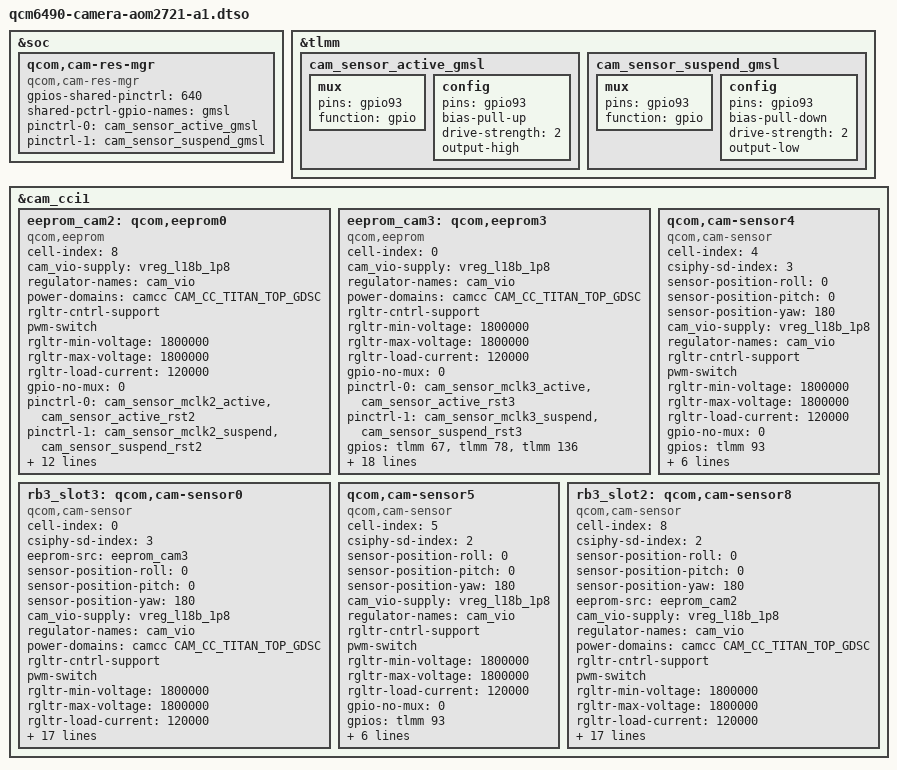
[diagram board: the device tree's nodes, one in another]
// SPDX-License-Identifier: BSD-3-Clause
/*
 * Copyright (c) 2023 Qualcomm Innovation Center, Inc. All rights reserved.
 */
/dts-v1/;
/plugin/;

#include <dt-bindings/clock/qcom,gcc-sc7280.h>
#include <dt-bindings/clock/qcom,camcc-sc7280.h>
#include <dt-bindings/interconnect/qcom,sc7280.h>
#include <dt-bindings/interrupt-controller/arm-gic.h>
#include <dt-bindings/power/qcom-rpmpd.h>

#include "qcm6490-camera-rb3.dtsi"

&soc {
	qcom,cam-res-mgr {
		compatible = "qcom,cam-res-mgr";
		status = "ok";
		gpios-shared-pinctrl = <640>;
		shared-pctrl-gpio-names = "gmsl";
		pinctrl-names = "gmsl_active", "gmsl_suspend";
		pinctrl-0 = <&cam_sensor_active_gmsl>;
		pinctrl-1 = <&cam_sensor_suspend_gmsl>;
	};
};
&tlmm {
	cam_sensor_active_gmsl: cam_sensor_active_gmsl {
		/* GMSL_ENABLE */
		mux {
			pins = "gpio93";
			function = "gpio";
		};

		config {
			pins = "gpio93";
			bias-pull-up;
			drive-strength = <2>; /* 2 MA */
			output-high;
		};
	};

	cam_sensor_suspend_gmsl: cam_sensor_suspend_gmsl {
		/* GMSL_ENABLE */
		mux {
			pins = "gpio93";
			function = "gpio";
		};

		config {
			pins = "gpio93";
			bias-pull-down; /* PULL DOWN */
			drive-strength = <2>; /* 2 MA */
			output-low;
		};
	};
};

&cam_cci1 {
	eeprom_cam2: qcom,eeprom0 {
		cell-index = <8>;
		compatible = "qcom,eeprom";
		cam_vio-supply = <&vreg_l18b_1p8>;
		regulator-names = "cam_vio";
		power-domains = <&camcc CAM_CC_TITAN_TOP_GDSC>;
		rgltr-cntrl-support;
		pwm-switch;
		rgltr-min-voltage = <1800000>;
		rgltr-max-voltage = <1800000>;
		rgltr-load-current = <120000>;
		gpio-no-mux = <0>;
		pinctrl-names = "cam_default", "cam_suspend";
		pinctrl-0 = <&cam_sensor_mclk2_active
				 &cam_sensor_active_rst2>;
		pinctrl-1 = <&cam_sensor_mclk2_suspend
				 &cam_sensor_suspend_rst2>;
		gpios = <&tlmm 66 0>,
			<&tlmm 77 0>,
			<&tlmm 137 0>;
		gpio-reset = <1>;
		gpio-custom1 = <2>;
		gpio-req-tbl-num = <0 1 2>;
		gpio-req-tbl-flags = <1 0 0>;
		gpio-req-tbl-label = "CAMIF_MCLK2",
					"CAM_RESET2",
					"CAM_CUSTOM1";
		sensor-mode = <0>;
		cci-master = <0>;
		status = "ok";
		clocks = <&camcc CAM_CC_MCLK2_CLK>;
		clock-names = "cam_clk";
		clock-cntl-level = "nominal";
		clock-rates = <24000000>;
	};

	eeprom_cam3: qcom,eeprom3 {
		cell-index = <0>;
		compatible = "qcom,eeprom";
		cam_vio-supply = <&vreg_l18b_1p8>;
		regulator-names = "cam_vio";
		power-domains = <&camcc CAM_CC_TITAN_TOP_GDSC>;
		rgltr-cntrl-support;
		rgltr-min-voltage = <1800000>;
		rgltr-max-voltage = <1800000>;
		rgltr-load-current = <120000>;
		gpio-no-mux = <0>;
		pinctrl-names = "cam_default", "cam_suspend";
		pinctrl-0 = <&cam_sensor_mclk3_active
			&cam_sensor_active_rst3>;
		pinctrl-1 = <&cam_sensor_mclk3_suspend
			&cam_sensor_suspend_rst3>;
		gpios = <&tlmm 67 0>,
			<&tlmm 78 0>,
			<&tlmm 136 0>;
		gpio-reset = <1>;
		gpio-custom1 = <2>;
		gpio-req-tbl-num = <0 1 2>;
		gpio-req-tbl-flags = <1 0 0>;
		gpio-req-tbl-label = "CAMIF_MCLK3",
			"CAM_RESET3",
			"CAM_CUSTOM1";
		sensor-position = <1>;
		sensor-mode = <0>;
		cci-master = <1>;
		qcom,cam-power-seq-type ="cam_reset","cam_vio","cam_clk","cam_reset";
		qcom,cam-power-seq-val = "cam_reset","cam_vio"
			,"cam_mclk","cam_reset";
		qcom,cam-power-seq-cfg-val = <0 1 24000000 1>;
		qcom,cam-power-seq-delay = <1 0 1 18>;
		status = "ok";
		clocks = <&camcc CAM_CC_MCLK3_CLK>;
		clock-names = "cam_clk";
		clock-cntl-level = "nominal";
		clock-rates = <24000000>;
	};

	/*cam3-imx577*/
	rb3_slot3: qcom,cam-sensor0 {
		cell-index = <0>;
		compatible = "qcom,cam-sensor";
		csiphy-sd-index = <3>;
		eeprom-src = <&eeprom_cam3>;
		sensor-position-roll = <0>;
		sensor-position-pitch = <0>;
		sensor-position-yaw = <180>;
		cam_vio-supply = <&vreg_l18b_1p8>;
		regulator-names = "cam_vio";
		power-domains = <&camcc CAM_CC_TITAN_TOP_GDSC>;
		rgltr-cntrl-support;
		pwm-switch;
		rgltr-min-voltage = <1800000>;
		rgltr-max-voltage = <1800000>;
		rgltr-load-current = <120000>;
		gpio-no-mux = <0>;
		pinctrl-names = "cam_default", "cam_suspend";
		pinctrl-0 = <&cam_sensor_mclk3_active
				&cam_sensor_active_rst3>;
		pinctrl-1 = <&cam_sensor_mclk3_suspend
				&cam_sensor_suspend_rst3>;
		gpios = <&tlmm 67 0>,
			<&tlmm 78 0>,
			<&tlmm 136 0>;
		gpio-reset = <1>;
		gpio-custom1 = <2>;
		gpio-req-tbl-num = <0 1 2>;
		gpio-req-tbl-flags = <1 0 0>;
		gpio-req-tbl-label = "CAMIF_MCLK3",
					"CAM_RESET3",
					"CAM_CUSTOM1";
		sensor-mode = <0>;
		cci-master = <1>;
		status = "ok";
		clocks = <&camcc CAM_CC_MCLK3_CLK>;
		clock-names = "cam_clk";
		clock-cntl-level = "nominal";
		clock-rates = <24000000>;
	};

	/* GMSL 1 */
	qcom,cam-sensor4 {
		cell-index = <4>;
		compatible = "qcom,cam-sensor";
		csiphy-sd-index = <3>;
		sensor-position-roll = <0>;
		sensor-position-pitch = <0>;
		sensor-position-yaw = <180>;
		cam_vio-supply = <&vreg_l18b_1p8>;
		regulator-names = "cam_vio";
		rgltr-cntrl-support;
		pwm-switch;
		rgltr-min-voltage = <1800000>;
		rgltr-max-voltage = <1800000>;
		rgltr-load-current = <120000>;
		gpio-no-mux = <0>;
		gpios = <&tlmm 93 0>;
		gpio-reset = <0>;
		gpio-req-tbl-num = <0>;
		gpio-req-tbl-flags = <0>;
		gpio-req-tbl-label = "CAM_4";
		sensor-mode = <0>;
		cci-master = <1>;
		status = "ok";
	};

	/* GMSL 2 */
	qcom,cam-sensor5 {
		cell-index = <5>;
		compatible = "qcom,cam-sensor";
		csiphy-sd-index = <2>;
		sensor-position-roll = <0>;
		sensor-position-pitch = <0>;
		sensor-position-yaw = <180>;
		cam_vio-supply = <&vreg_l18b_1p8>;
		regulator-names = "cam_vio";
		rgltr-cntrl-support;
		pwm-switch;
		rgltr-min-voltage = <1800000>;
		rgltr-max-voltage = <1800000>;
		rgltr-load-current = <120000>;
		gpio-no-mux = <0>;
		gpios = <&tlmm 93 0>;
		gpio-reset = <0>;
		gpio-req-tbl-num = <0>;
		gpio-req-tbl-flags = <0>;
		gpio-req-tbl-label = "CAM_5";
		sensor-mode = <0>;
		cci-master = <1>;
		status = "ok";
	};

	/*cam2-imx577*/
	rb3_slot2: qcom,cam-sensor8 {
		cell-index = <8>;
		compatible = "qcom,cam-sensor";
		csiphy-sd-index = <2>;
		sensor-position-roll = <0>;
		sensor-position-pitch = <0>;
		sensor-position-yaw = <180>;
		eeprom-src = <&eeprom_cam2>;
		cam_vio-supply = <&vreg_l18b_1p8>;
		regulator-names = "cam_vio";
		power-domains = <&camcc CAM_CC_TITAN_TOP_GDSC>;
		rgltr-cntrl-support;
		pwm-switch;
		rgltr-min-voltage = <1800000>;
		rgltr-max-voltage = <1800000>;
		rgltr-load-current = <120000>;
		gpio-no-mux = <0>;
		pinctrl-names = "cam_default", "cam_suspend";
		pinctrl-0 = <&cam_sensor_mclk2_active
				 &cam_sensor_active_rst2>;
		pinctrl-1 = <&cam_sensor_mclk2_suspend
				 &cam_sensor_suspend_rst2>;
		gpios = <&tlmm 66 0>,
			<&tlmm 77 0>,
			<&tlmm 137 0>;
		gpio-reset = <1>;
		gpio-custom1 = <2>;
		gpio-req-tbl-num = <0 1 2>;
		gpio-req-tbl-flags = <1 0 0>;
		gpio-req-tbl-label = "CAMIF_MCLK2",
					"CAM_RESET2",
					"CAM_CUSTOM1";
		sensor-mode = <0>;
		cci-master = <0>;
		status = "ok";
		clocks = <&camcc CAM_CC_MCLK2_CLK>;
		clock-names = "cam_clk";
		clock-cntl-level = "nominal";
		clock-rates = <24000000>;
	};
};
